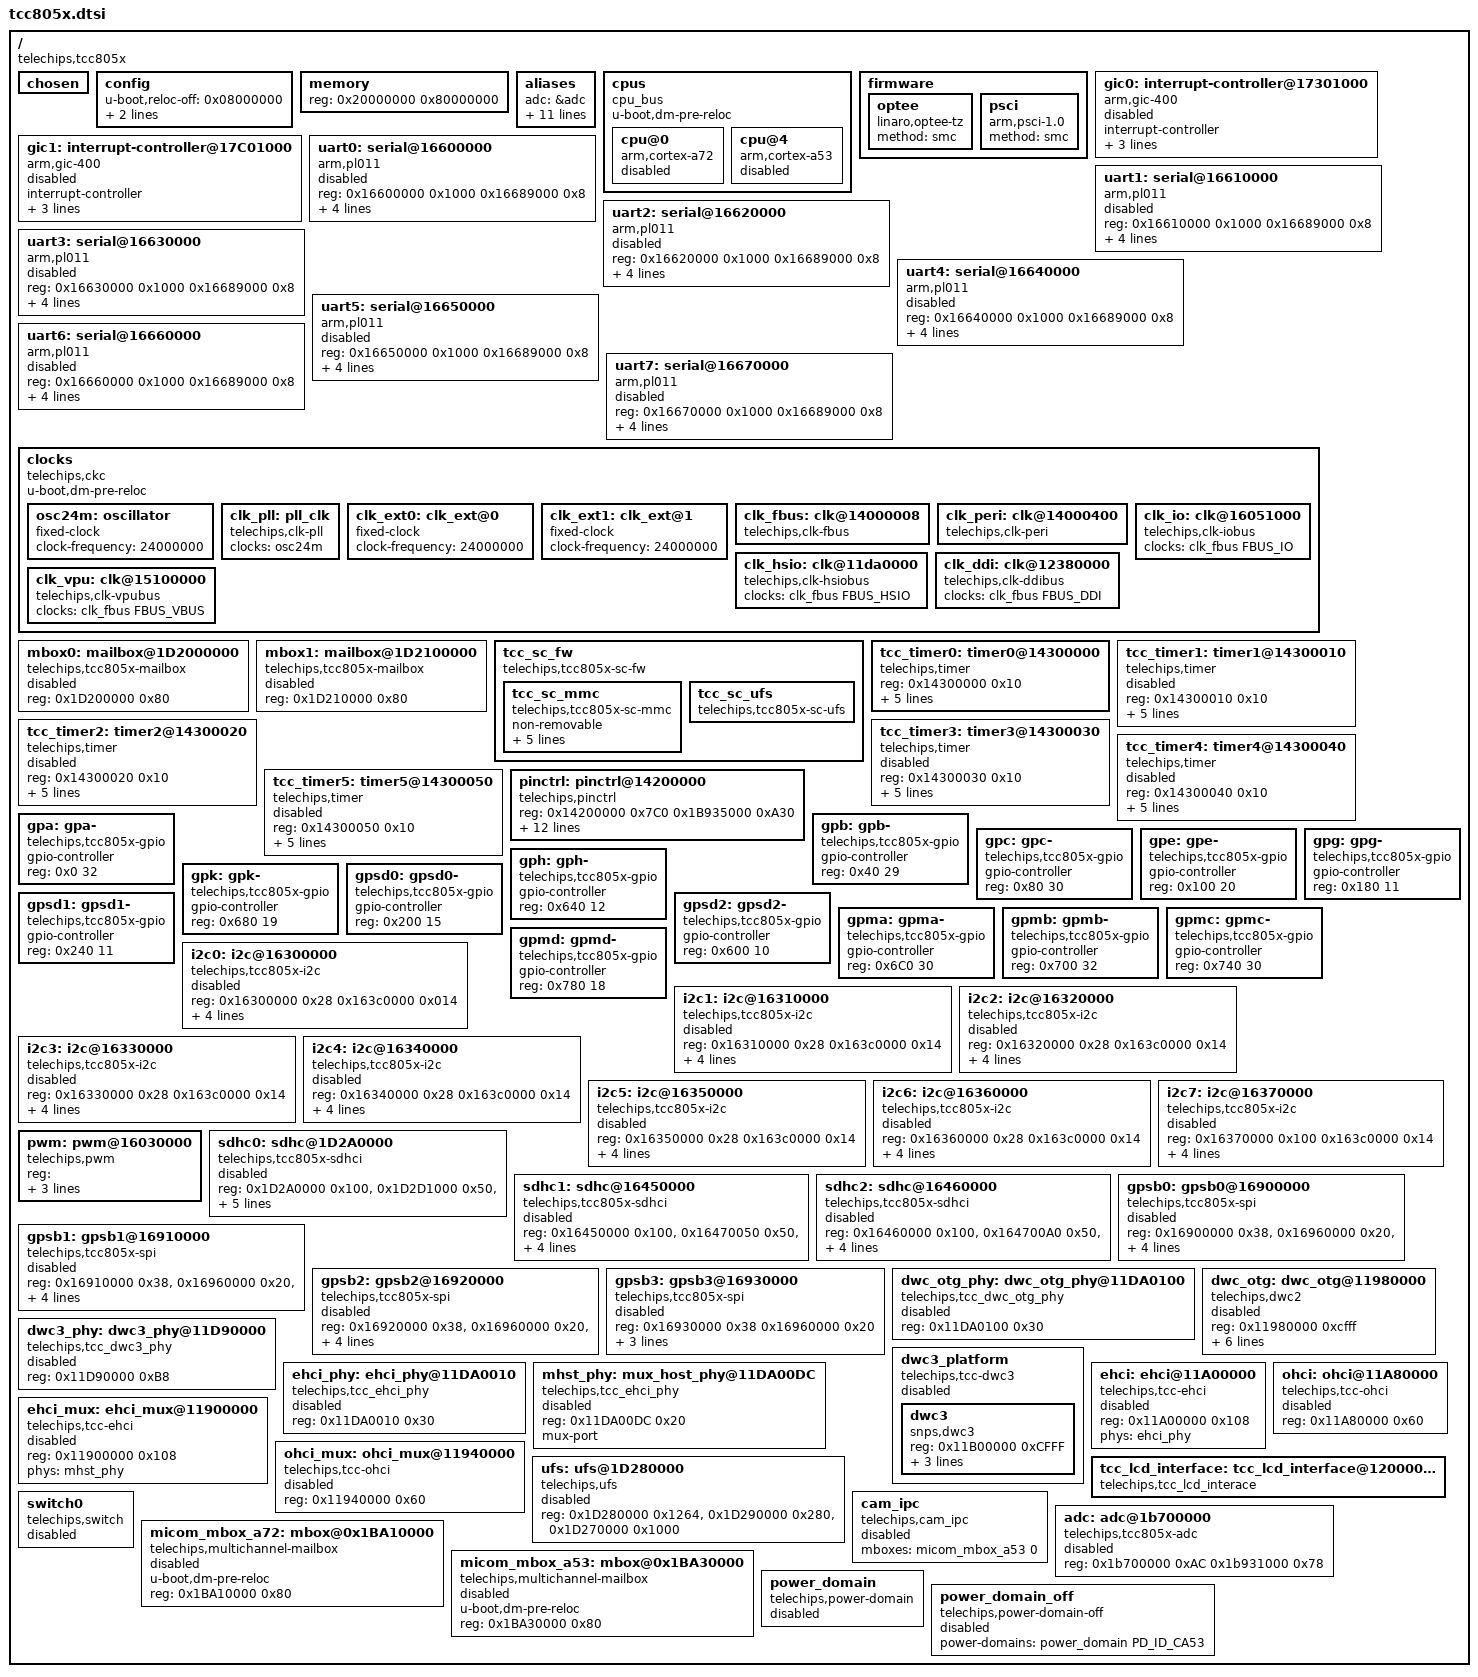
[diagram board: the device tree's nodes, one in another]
// SPDX-License-Identifier: (GPL-2.0-or-later OR MIT)
/*
 * Copyright (C) Telechips Inc.
 */

#include <dt-bindings/board/telechips.h>
#include <dt-bindings/clock/telechips,tcc805x-clks.h>
#include <dt-bindings/display/tcc805x-vioc.h>
#include <dt-bindings/gpio/gpio.h>
#include <dt-bindings/interrupt-controller/arm-gic.h>
#include <dt-bindings/power-domain/telechips-power-domain.h>

/ {
	compatible = "telechips,tcc805x";

	#address-cells = <1>;
	#size-cells = <1>;

	chosen: chosen {};

	config: config {
		u-boot,reloc-off = <0x08000000>;
		u-boot,mmc-env-partition = "env";
		u-boot,scsi-env-partition = "env";
	};

	memory: memory {
		device_type = "memory";
		reg = <0x20000000 0x80000000>;
	};

	aliases: aliases {
		adc = &adc;
		i2c0 = &i2c0;
		i2c1 = &i2c1;
		i2c2 = &i2c2;
		i2c3 = &i2c3;
		i2c4 = &i2c4;
		i2c5 = &i2c5;
		i2c6 = &i2c6;
		i2c7 = &i2c7;
		mmc0 = &sdhc0;
		mmc1 = &sdhc1;
		mmc2 = &sdhc2;
	};

	cpus: cpus {
		compatible = "cpu_bus";
		u-boot,dm-pre-reloc;

		cpu@0 {
			compatible = "arm,cortex-a72";
			device_type = "cpu";

			status = "disabled";
		};

		cpu@4 {
			compatible = "arm,cortex-a53";
			device_type = "cpu";

			status = "disabled";
		};
	};

	firmware {
		optee {
			compatible = "linaro,optee-tz";
			method = "smc";
		};

		psci: psci {
			compatible = "arm,psci-1.0";
			method = "smc";
		};
	};

	gic0: interrupt-controller@17301000 {
		compatible = "arm,gic-400", "telechips,tcc805x-vpic";
		#interrupt-cells = <3>;
		#address-cells = <0>;
		interrupt-controller;
		reg = <0x17301000 0x1000>,
		      <0x17302000 0x1000>,
		      <0x17304000 0x2000>,
		      <0x17306000 0x2000>,
		      <0x141000E0 0x18>,
		      <0x14600100 0x24>;

		status = "disabled";
	};

	gic1: interrupt-controller@17C01000 {
		compatible = "arm,gic-400", "telechips,tcc805x-vpic";
		#interrupt-cells = <3>;
		#address-cells = <0>;
		interrupt-controller;
		reg = <0x17C01000 0x1000>,
		      <0x17C02000 0x1000>,
		      <0x17C04000 0x2000>,
		      <0x17C06000 0x2000>,
		      <0x141000E0 0x18>,
		      <0x14600100 0x24>;

		status = "disabled";
	};

	uart0: serial@16600000 {
		compatible = "arm,pl011", "arm,primecell";
		reg = <0x16600000 0x1000 0x16689000 0x8>;
		interrupts = <GIC_SPI 88 IRQ_TYPE_LEVEL_HIGH>;
		clocks = <&clk_peri PERI_UART0>, <&clk_io IOBUS_UART0>;
		clock = <48000000>;
		status = "disabled";
	};

	uart1: serial@16610000 {
		compatible = "arm,pl011", "arm,primecell";
		reg = <0x16610000 0x1000 0x16689000 0x8>;
		interrupts = <GIC_SPI 89 IRQ_TYPE_LEVEL_HIGH>;
		clocks = <&clk_peri PERI_UART1>, <&clk_io IOBUS_UART1>;
		clock = <48000000>;
		status = "disabled";
	};

	uart2: serial@16620000 {
		compatible = "arm,pl011", "arm,primecell";
		reg = <0x16620000 0x1000 0x16689000 0x8>;
		interrupts = <GIC_SPI 90 IRQ_TYPE_LEVEL_HIGH>;
		clocks = <&clk_peri PERI_UART2>, <&clk_io IOBUS_UART2>;
		clock = <48000000>;
		status = "disabled";
	};

	uart3: serial@16630000 {
		compatible = "arm,pl011", "arm,primecell";
		reg = <0x16630000 0x1000 0x16689000 0x8>;
		interrupts = <GIC_SPI 91 IRQ_TYPE_LEVEL_HIGH>;
		clocks = <&clk_peri PERI_UART3>, <&clk_io IOBUS_UART3>;
		clock = <48000000>;
		status = "disabled";
	};

	uart4: serial@16640000 {
		compatible = "arm,pl011", "arm,primecell";
		reg = <0x16640000 0x1000 0x16689000 0x8>;
		interrupts = <GIC_SPI 69 IRQ_TYPE_LEVEL_HIGH>;
		clocks = <&clk_peri PERI_UART4>, <&clk_io IOBUS_UART4>;
		clock = <48000000>;
		status = "disabled";
	};

	uart5: serial@16650000 {
		compatible = "arm,pl011", "arm,primecell";
		reg = <0x16650000 0x1000 0x16689000 0x8>;
		interrupts = <GIC_SPI 111 IRQ_TYPE_LEVEL_HIGH>;
		clocks = <&clk_peri PERI_UART5>, <&clk_io IOBUS_UART5>;
		clock = <48000000>;
		status = "disabled";
	};

	uart6: serial@16660000 {
		compatible = "arm,pl011", "arm,primecell";
		reg = <0x16660000 0x1000 0x16689000 0x8>;
		interrupts = <GIC_SPI 112 IRQ_TYPE_LEVEL_HIGH>;
		clocks = <&clk_peri PERI_UART6>, <&clk_io IOBUS_UART6>;
		clock = <48000000>;
		status = "disabled";
	};

	uart7: serial@16670000 {
		compatible = "arm,pl011", "arm,primecell";
		reg = <0x16670000 0x1000 0x16689000 0x8>;
		interrupts = <GIC_SPI 113 IRQ_TYPE_LEVEL_HIGH>;
		clocks = <&clk_peri PERI_UART7>, <&clk_io IOBUS_UART7>;
		clock = <48000000>;
		status = "disabled";
	};

	clocks {
		compatible = "telechips,ckc";
		u-boot,dm-pre-reloc;

		osc24m: oscillator {
			compatible = "fixed-clock";
			#clock-cells = <0>;
			clock-frequency = <24000000>;
		};

		clk_pll: pll_clk {
			compatible = "telechips,clk-pll";
			#clock-cells = <1>;
			clocks = <&osc24m>;
		};

		clk_ext0: clk_ext@0 {
			compatible = "fixed-clock";
			#clock-cells = <0>;
			clock-frequency = <24000000>;
		};

		clk_ext1: clk_ext@1 {
			compatible = "fixed-clock";
			#clock-cells = <0>;
			clock-frequency = <24000000>;
		};

		clk_fbus: clk@14000008 {
			compatible = "telechips,clk-fbus";
			#clock-cells = <1>;
		};

		clk_peri: clk@14000400 {
			compatible = "telechips,clk-peri";
			#clock-cells = <1>;
		};

		clk_io: clk@16051000 {
			compatible = "telechips,clk-iobus";
			#clock-cells = <1>;
			clocks = <&clk_fbus FBUS_IO>;
		};

		clk_hsio: clk@11da0000 {
			compatible = "telechips,clk-hsiobus";
			#clock-cells = <1>;
			clocks = <&clk_fbus FBUS_HSIO>;
		};

		clk_ddi: clk@12380000 {
			compatible = "telechips,clk-ddibus";
			#clock-cells = <1>;
			clocks = <&clk_fbus FBUS_DDI>;
		};

		clk_vpu: clk@15100000 {
			compatible = "telechips,clk-vpubus";
			#clock-cells = <1>;
			clocks = <&clk_fbus FBUS_VBUS>;
		};
	};

	/* storage bus mailbox for ca72 */
	mbox0: mailbox@1D2000000 {
		compatible = "telechips,tcc805x-mailbox";
		status = "disabled";
		reg = <0x1D200000 0x80>;
		#mbox-cells = <1>;
	};

	/* storage bus mailbox for ca53 */
	mbox1: mailbox@1D2100000 {
		compatible = "telechips,tcc805x-mailbox";
		status = "disabled";
		reg = <0x1D210000 0x80>;
		#mbox-cells = <1>;
	};

	tcc_sc_fw: tcc_sc_fw {
		compatible = "telechips,tcc805x-sc-fw";

		tcc_sc_mmc: tcc_sc_mmc {
			compatible = "telechips,tcc805x-sc-mmc";
			non-removable;
			mmc-hs200-1_8v;
			mmc-hs400-1_8v;
			bus-width = <8>;
			max-frequency = <200000000>;
			controller-id = <1>;
		};

		tcc_sc_ufs: tcc_sc_ufs {
			compatible = "telechips,tcc805x-sc-ufs";
		};
	};

	tcc_timer0: timer0@14300000 {
		compatible = "telechips,timer";
		reg = <0x14300000 0x10>;
		id = <0>;
		width = <16>;
		interrupts = <GIC_SPI 33 0>;
		clocks = <&clk_peri PERI_TCT>;
		clock-frequency = <12000000>;
	};

	tcc_timer1: timer1@14300010 {
		compatible = "telechips,timer";
		reg = <0x14300010 0x10>;
		id = <1>;
		width = <16>;
		interrupts = <GIC_SPI 34 0>;
		clocks = <&clk_peri PERI_TCT>;
		clock-frequency = <12000000>;
		status = "disabled";
	};

	tcc_timer2: timer2@14300020 {
		compatible = "telechips,timer";
		reg = <0x14300020 0x10>;
		id = <2>;
		width = <16>;
		interrupts = <GIC_SPI 35 0>;
		clocks = <&clk_peri PERI_TCT>;
		clock-frequency = <12000000>;
		status = "disabled";
	};

	tcc_timer3: timer3@14300030 {
		compatible = "telechips,timer";
		reg = <0x14300030 0x10>;
		id = <3>;
		width = <16>;
		interrupts = <GIC_SPI 36 0>;
		clocks = <&clk_peri PERI_TCT>;
		clock-frequency = <12000000>;
		status = "disabled";
	};

	tcc_timer4: timer4@14300040 {
		compatible = "telechips,timer";
		reg = <0x14300040 0x10>;
		id = <4>;
		width = <20>;
		interrupts = <GIC_SPI 37 0>;
		clocks = <&clk_peri PERI_TCT>;
		clock-frequency = <12000000>;
		status = "disabled";
	};

	tcc_timer5: timer5@14300050 {
		compatible = "telechips,timer";
		reg = <0x14300050 0x10>;
		id = <5>;
		width = <20>;
		interrupts = <GIC_SPI 38 0>;
		clocks = <&clk_peri PERI_TCT>;
		clock-frequency = <12000000>;
		status = "disabled";
	};

	pinctrl: pinctrl@14200000 {
		compatible = "telechips,pinctrl";
		reg = <0x14200000 0x7C0 0x1B935000 0xA30>; /* gpio, pmgpio */
		gpio-controller;
		#address-cells = <1>;
		#size-cells = <0>;
		#gpio-cells = <3>;
		interrupts = <GIC_SPI 0 0>,
			     <GIC_SPI 1 0>,
			     <GIC_SPI 2 0>,
			     <GIC_SPI 3 0>,
			     <GIC_SPI 4 0>,
			     <GIC_SPI 5 0>,
			     <GIC_SPI 6 0>,
			     <GIC_SPI 7 0>,
			     <GIC_SPI 8 0>,
			     <GIC_SPI 9 0>,
			     <GIC_SPI 10 0>,
			     <GIC_SPI 11 0>,
			     <GIC_SPI 12 0>,
			     <GIC_SPI 13 0>,
			     <GIC_SPI 14 0>,
			     <GIC_SPI 15 0>,
			     <GIC_SPI 16 0>,
			     <GIC_SPI 17 0>,
			     <GIC_SPI 18 0>,
			     <GIC_SPI 19 0>,
			     <GIC_SPI 20 0>,
			     <GIC_SPI 21 0>,
			     <GIC_SPI 22 0>,
			     <GIC_SPI 23 0>,
			     <GIC_SPI 24 0>,
			     <GIC_SPI 25 0>,
			     <GIC_SPI 26 0>,
			     <GIC_SPI 27 0>,
			     <GIC_SPI 28 0>,
			     <GIC_SPI 29 0>,
			     <GIC_SPI 30 0>,
			     <GIC_SPI 31 0>;
	};

	gpa: gpa- {
		compatible = "telechips,tcc805x-gpio";
		gpio-controller;
		#gpio-cells = <2>;
		reg = <0x0 32>;
	};

	gpb: gpb- {
		compatible = "telechips,tcc805x-gpio";
		gpio-controller;
		#gpio-cells = <2>;
		reg = <0x40 29>;
	};

	gpc: gpc- {
		compatible = "telechips,tcc805x-gpio";
		gpio-controller;
		#gpio-cells = <2>;
		reg = <0x80 30>;
	};

	gpe: gpe- {
		compatible = "telechips,tcc805x-gpio";
		gpio-controller;
		#gpio-cells = <2>;
		reg = <0x100 20>;
	};

	gpg: gpg- {
		compatible = "telechips,tcc805x-gpio";
		gpio-controller;
		#gpio-cells = <2>;
		reg = <0x180 11>;
	};

	gph: gph- {
		compatible = "telechips,tcc805x-gpio";
		gpio-controller;
		#gpio-cells = <2>;
		reg = <0x640 12>;
	};

	gpk: gpk- {
		compatible = "telechips,tcc805x-gpio";
		gpio-controller;
		#gpio-cells = <2>;
		reg = <0x680 19>;
	};

	gpsd0: gpsd0- {
		compatible = "telechips,tcc805x-gpio";
		gpio-controller;
		#gpio-cells = <2>;
		reg = <0x200 15>;
	};

	gpsd1: gpsd1- {
		compatible = "telechips,tcc805x-gpio";
		gpio-controller;
		#gpio-cells = <2>;
		reg = <0x240 11>;
	};

	gpsd2: gpsd2- {
		compatible = "telechips,tcc805x-gpio";
		gpio-controller;
		#gpio-cells = <2>;
		reg = <0x600 10>;
	};

	gpma: gpma- {
		compatible = "telechips,tcc805x-gpio";
		gpio-controller;
		#gpio-cells = <2>;
		reg = <0x6C0 30>;
	};

	gpmb: gpmb- {
		compatible = "telechips,tcc805x-gpio";
		gpio-controller;
		#gpio-cells = <2>;
		reg = <0x700 32>;
	};

	gpmc: gpmc- {
		compatible = "telechips,tcc805x-gpio";
		gpio-controller;
		#gpio-cells = <2>;
		reg = <0x740 30>;
	};

	gpmd: gpmd- {
		compatible = "telechips,tcc805x-gpio";
		gpio-controller;
		#gpio-cells = <2>;
		reg = <0x780 18>;
	};

	i2c0: i2c@16300000 {
		compatible = "telechips,tcc805x-i2c";
		reg = <0x16300000 0x28 0x163c0000 0x014>;
		#address-cells = <1>;
		#size-cells = <0>;
		clocks = <&clk_peri PERI_I2C0 &clk_io IOBUS_I2C_M0
			  &clk_fbus FBUS_IO>;
		clock-frequency = <400000>;
		port-mux = <0xFF>;	/* default value */
		status = "disabled";
	};

	i2c1: i2c@16310000 {
		compatible = "telechips,tcc805x-i2c";
		reg = <0x16310000 0x28 0x163c0000 0x14>;
		#address-cells = <1>;
		#size-cells = <0>;
		clocks = <&clk_peri PERI_I2C1 &clk_io IOBUS_I2C_M1
			  &clk_fbus FBUS_IO>;
		clock-frequency = <400000>;
		port-mux = <0xFF>;	/* default value */
		status = "disabled";
	};

	i2c2: i2c@16320000 {
		compatible = "telechips,tcc805x-i2c";
		reg = <0x16320000 0x28 0x163c0000 0x14>;
		#address-cells = <1>;
		#size-cells = <0>;
		clocks = <&clk_peri PERI_I2C2 &clk_io IOBUS_I2C_M2
			  &clk_fbus FBUS_IO>;
		clock-frequency = <400000>;
		port-mux = <0xFF>;	/* default value */
		status = "disabled";
	};

	i2c3: i2c@16330000 {
		compatible = "telechips,tcc805x-i2c";
		reg = <0x16330000 0x28 0x163c0000 0x14>;
		#address-cells = <1>;
		#size-cells = <0>;
		clocks = <&clk_peri PERI_I2C3 &clk_io IOBUS_I2C_M3
			  &clk_fbus FBUS_IO>;
		clock-frequency = <400000>;
		port-mux = <0xFF>;	/* default value */
		status = "disabled";
	};

	i2c4: i2c@16340000 {
		compatible = "telechips,tcc805x-i2c";
		reg = <0x16340000 0x28 0x163c0000 0x14>;
		#address-cells = <1>;
		#size-cells = <0>;
		clocks = <&clk_peri PERI_I2C0 &clk_io IOBUS_I2C_M4
			  &clk_fbus FBUS_IO>;
		clock-frequency = <400000>;
		port-mux = <0xFF>;	/* default value */
		status = "disabled";
	};

	i2c5: i2c@16350000 {
		compatible = "telechips,tcc805x-i2c";
		reg = <0x16350000 0x28 0x163c0000 0x14>;
		#address-cells = <1>;
		#size-cells = <0>;
		clocks = <&clk_peri PERI_I2C1 &clk_io IOBUS_I2C_M5
			  &clk_fbus FBUS_IO>;
		clock-frequency = <400000>;
		port-mux = <0xFF>;	/* default value */
		status = "disabled";
	};

	i2c6: i2c@16360000 {
		compatible = "telechips,tcc805x-i2c";
		reg = <0x16360000 0x28 0x163c0000 0x14>;
		#address-cells = <1>;
		#size-cells = <0>;
		clocks = <&clk_peri PERI_I2C2 &clk_io IOBUS_I2C_M6
			  &clk_fbus FBUS_IO>;
		clock-frequency = <400000>;
		port-mux = <0xFF>;	/* default value */
		status = "disabled";
	};

	i2c7: i2c@16370000 {
		compatible = "telechips,tcc805x-i2c";
		reg = <0x16370000 0x100 0x163c0000 0x14>;
		#address-cells = <1>;
		#size-cells = <0>;
		clocks = <&clk_peri PERI_I2C3 &clk_io IOBUS_I2C_M7
			  &clk_fbus FBUS_IO>;
		clock-frequency = <400000>;
		port-mux = <0xFF>;	/* default value */
		status = "disabled";
	};

	pwm:pwm@16030000 {
		compatible = "telechips,pwm";
		reg = <0x16030000 0x94 0x1605104C 0x4 0x16051094 0x4>;
		tcc,pwm-number = <4>;
		#pwm-cells = <2>;
		clocks = <&clk_peri PERI_PDM &clk_io IOBUS_PWM>;
		status = "okay";
	};

	sdhc0: sdhc@1D2A0000 {
		compatible = "telechips,tcc805x-sdhci";
		reg = <0x1D2A0000 0x100>,
		      <0x1D2D1000 0x50>,
		      <0x1D2D10FC 0x30>,
		      <0x1D2D112C 0x24>;
		max-frequency = <200000000>;
		peri-clock-frequency = <2600000000>;
		bus-width = <4>;
		controller-id = <0>;
		status = "disabled";
	};

	sdhc1: sdhc@16450000 {
		compatible = "telechips,tcc805x-sdhci";
		reg = <0x16450000 0x100>,
		      <0x16470050 0x50>,
		      <0x164700FC 0x30>,
		      <0x16470150 0x24>;
		max-frequency = <50000000>;
		bus-width = <4>;
		controller-id = <1>;
		status = "disabled";
	};

	sdhc2: sdhc@16460000 {
		compatible = "telechips,tcc805x-sdhci";
		reg = <0x16460000 0x100>,
		      <0x164700A0 0x50>,
		      <0x164700FC 0x30>,
		      <0x16470174 0x24>;
		max-frequency = <50000000>;
		bus-width = <4>;
		controller-id = <2>;
		status = "disabled";
	};

	gpsb0: gpsb0@16900000 {
		compatible = "telechips,tcc805x-spi";
		reg = <0x16900000 0x38>, /* base address */
		      <0x16960000 0x20>, /* Port Configuration register */
		      <0x16980000 0x20>; /* GPSB_0_AC */
		interrupts = <GIC_SPI 55 IRQ_TYPE_LEVEL_HIGH>;
		clocks = <&clk_peri PERI_GPSB0 &clk_io IOBUS_GPSB0>;
		status = "disabled";

		//access-control0 = <0x20000000 0xC0000000>; /* DRAM */
		//access-control1 = <0x00000000 0x00000000>;
		//access-control2 = <0x00000000 0x00000000>;
		//access-control3 = <0x00000000 0x00000000>;
	};

	gpsb1: gpsb1@16910000 {
		compatible = "telechips,tcc805x-spi";
		reg = <0x16910000 0x38>, /* base address */
		      <0x16960000 0x20>, /* Port Configuration register */
		      <0x16970000 0x84>, /* PID register */
		      <0x16980020 0x20>; /* GPSB_1_AC */
		interrupts = <GIC_SPI 56 IRQ_TYPE_LEVEL_HIGH>;
		clocks = <&clk_peri PERI_GPSB1 &clk_io IOBUS_GPSB1>;
		status = "disabled";

		//access-control0 = <0x20000000 0xC0000000>; /* DRAM */
		//access-control1 = <0x00000000 0x00000000>;
		//access-control2 = <0x00000000 0x00000000>;
		//access-control3 = <0x00000000 0x00000000>;
	};

	gpsb2: gpsb2@16920000 {
		compatible = "telechips,tcc805x-spi";
		reg = <0x16920000 0x38>, /* base address */
		      <0x16960000 0x20>, /* Port Configuration register */
		      <0x16970000 0x84>, /* PID register */
		      <0x16980040 0x20>; /* GPSB_2_AC */
		interrupts = <GIC_SPI 57 IRQ_TYPE_LEVEL_HIGH>;
		clocks = <&clk_peri PERI_GPSB2 &clk_io IOBUS_GPSB2>;
		status = "disabled";

		//access-control0 = <0x20000000 0xC0000000>; /* DRAM */
		//access-control1 = <0x00000000 0x00000000>;
		//access-control2 = <0x00000000 0x00000000>;
		//access-control3 = <0x00000000 0x00000000>;
	};

	gpsb3: gpsb3@16930000 {
		compatible = "telechips,tcc805x-spi";
		reg = <0x16930000 0x38 0x16960000 0x20>;
		interrupts = <GIC_SPI 58 IRQ_TYPE_LEVEL_HIGH>;
		clocks = <&clk_peri PERI_GPSBMS0 &clk_io IOBUS_GPSB3>;
		status = "disabled";
	};

	dwc_otg_phy: dwc_otg_phy@11DA0100 {
		compatible = "telechips,tcc_dwc_otg_phy";
		reg = <0x11DA0100 0x30>;
		#phy-cells = <0>;
		status = "disabled";
	};

	dwc_otg: dwc_otg@11980000 {
		compatible = "telechips,dwc2";
		reg = <0x11980000 0xcfff>;
		phys = <&dwc_otg_phy>;
		phy-names = "usb2-phy";
		dr_mode = "peripheral";
		g-np-tx-fifo-size = <16>;
		g-rx-fifo-size = <275>;
		g-tx-fifo-size = <256 128 128 64 64 32>;
		g-use-dma;
		status = "disabled";
	};


	dwc3_phy: dwc3_phy@11D90000 {
		compatible = "telechips,tcc_dwc3_phy";
		reg = <0x11D90000 0xB8>;
		#phy-cells = <0>;
		//support-bc12;
		//support-line-state;
		status = "disabled";
	};

	dwc3_platform: dwc3_platform {
		compatible = "telechips,tcc-dwc3";
		#address-cells = <1>;
		#size-cells = <1>;
		status = "disabled";
		ranges;

		dwc3: dwc3 {
			compatible = "snps,dwc3";
			reg = <0x11B00000 0xCFFF>;
			phys = <&dwc3_phy>;
			dr_mode = "host";
			maximum-speed = "super-speed";
		};
	};

	ehci_phy: ehci_phy@11DA0010 {
		compatible = "telechips,tcc_ehci_phy";
		reg = <0x11DA0010 0x30>;
		#phy-cells = <0>;
		//support-bc12;
		//support-line-state;
		status = "disabled";
	};

	mhst_phy: mux_host_phy@11DA00DC {
		compatible = "telechips,tcc_ehci_phy";
		reg = <0x11DA00DC 0x20>;
		#phy-cells = <0>;
		mux-port;
		//support-bc12;
		//support-line-state;
		status = "disabled";
	};

	ehci: ehci@11A00000 {
		compatible = "telechips,tcc-ehci";
		reg = <0x11A00000 0x108>;
		phys = <&ehci_phy>;
		status = "disabled";
	};

	ehci_mux: ehci_mux@11900000 {
		compatible = "telechips,tcc-ehci";
		reg = <0x11900000 0x108>;
		phys = <&mhst_phy>;
		status = "disabled";
	};

	ohci: ohci@11A80000 {
		compatible = "telechips,tcc-ohci";
		reg = <0x11A80000 0x60>;
		status = "disabled";
	};

	ohci_mux: ohci_mux@11940000 {
		compatible = "telechips,tcc-ohci";
		reg = <0x11940000 0x60>;
		status = "disabled";
	};

	ufs: ufs@1D280000 {
		compatible = "telechips,ufs";
		reg = <0x1D280000 0x1264>, /* HCI */
			<0x1D290000 0x280>,    /* FMP */
			<0x1D270000 0x1000>;   /* UniPro */
		clock-names = "ref_clk", "phy_clk";
		status = "disabled";
	};

	tcc_lcd_interface: tcc_lcd_interface@12000000{
		compatible = "telechips,tcc_lcd_interace";
	};

	switch0:switch0 {
		compatible = "telechips,switch";
		status = "disabled";
	};

	cam_ipc:cam_ipc {
		compatible = "telechips,cam_ipc";
		status = "disabled";
		mboxes = <&micom_mbox_a53 0>;
	};
	adc: adc@1b700000{
		compatible = "telechips,tcc805x-adc";
		reg = <0x1b700000 0xAC 0x1b931000 0x78>;
		status = "disabled";
	};

	/* MBOX for A72 with R5 */
	micom_mbox_a72: mbox@0x1BA10000 {
		compatible = "telechips,multichannel-mailbox";
		u-boot,dm-pre-reloc;
		status = "disabled";
		reg = <0x1BA10000 0x80>;
		#mbox-cells = <1>;
	};

	/* MBOX for A53 with R5 */
	micom_mbox_a53: mbox@0x1BA30000 {
		compatible = "telechips,multichannel-mailbox";
		u-boot,dm-pre-reloc;
		status = "disabled";
		reg = <0x1BA30000 0x80>;
		#mbox-cells = <1>;
	};

	power_domain: power_domain {
		compatible = "telechips,power-domain";
		#power-domain-cells = <1>;
		status = "disabled";
	};

	power_domain_off: power_domain_off {
		compatible = "telechips,power-domain-off";
		power-domains = <&power_domain PD_ID_CA53>;
		status = "disabled";
	};
};
